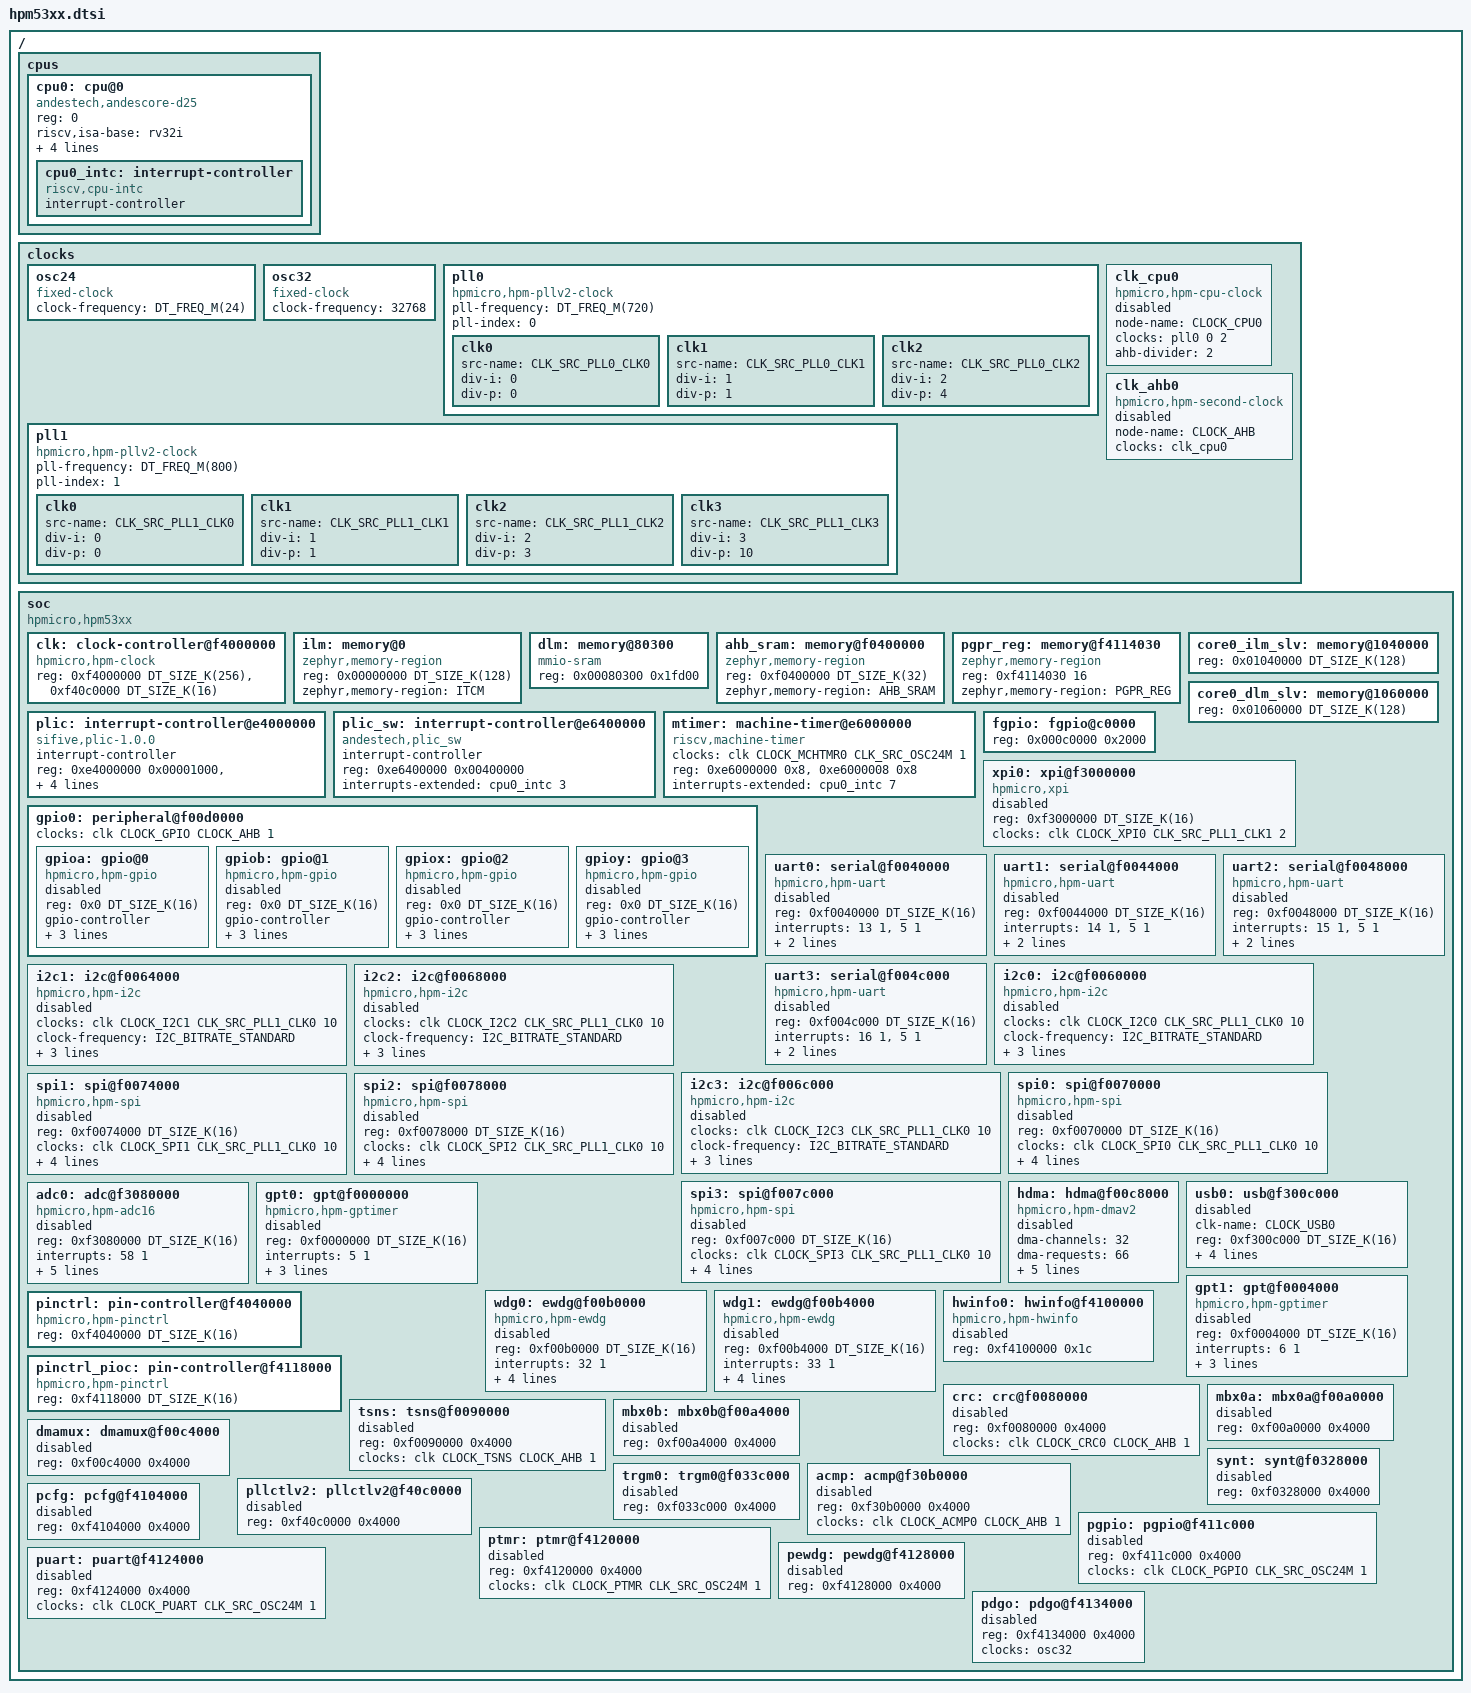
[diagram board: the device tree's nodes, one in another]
/*
* Copyright (c) 2026 HPMicro
* SPDX-License-Identifier: Apache-2.0
*/

/dts-v1/;

#include <zephyr/dt-bindings/gpio/gpio.h>
#include <zephyr/dt-bindings/i2c/i2c.h>
#include <mem.h>
#include <freq.h>

/ {
	#address-cells = <1>;
	#size-cells = <1>;
	cpus {
		#address-cells = <1>;
		#size-cells = <0>;
		cpu0: cpu@0 {
			compatible = "andestech,andescore-d25", "riscv";
			reg = <0>;
			status = "okay";
			riscv,isa-base = "rv32i";
			riscv,isa-extensions = "i", "m", "a", "c", "f", "d", "b", "p", "zicsr", "zifencei",
				"xandes";
			i-cache-line-size = <32>;
			d-cache-line-size = <32>;
			cpu0_intc: interrupt-controller {
				compatible = "riscv,cpu-intc";
				#address-cells = <0>;
				#interrupt-cells = <1>;
				interrupt-controller;
			};
		};
	};

	clocks {
		osc24: osc24 {
			#clock-cells = <0>;
			compatible = "fixed-clock";
			clock-frequency = <DT_FREQ_M(24)>;
		};

		osc32: osc32 {
			#clock-cells = <0>;
			compatible = "fixed-clock";
			clock-frequency = <32768>;
		};

		pll0: pll0 {
			#clock-cells = <2>;
			compatible = "hpmicro,hpm-pllv2-clock";
			pll-frequency = <DT_FREQ_M(720)>;
			pll-index = <0>;
			clk0 {
				src-name = <CLK_SRC_PLL0_CLK0>;
				div-i = <0>;
				div-p = <0>;
			};

			clk1 {
				src-name = <CLK_SRC_PLL0_CLK1>;
				div-i = <1>;
				div-p = <1>;
			};

			clk2 {
				src-name = <CLK_SRC_PLL0_CLK2>;
				div-i = <2>;
				div-p = <4>;
			};
		};

		pll1: pll1 {
			#clock-cells = <2>;
			compatible = "hpmicro,hpm-pllv2-clock";
			pll-frequency = <DT_FREQ_M(800)>;
			pll-index = <1>;
			clk0 {
				src-name = <CLK_SRC_PLL1_CLK0>;
				div-i = <0>;
				div-p = <0>;
			};

			clk1 {
				src-name = <CLK_SRC_PLL1_CLK1>;
				div-i = <1>;
				div-p = <1>;
			};

			clk2 {
				src-name = <CLK_SRC_PLL1_CLK2>;
				div-i = <2>;
				div-p = <3>;
			};

			clk3 {
				src-name = <CLK_SRC_PLL1_CLK3>;
				div-i = <3>;
				div-p = <10>;
			};
		};

		clk_cpu0: clk_cpu0 {
			#clock-cells = <0>;
			compatible = "hpmicro,hpm-cpu-clock";
			node-name = <CLOCK_CPU0>;
			clocks = <&pll0 0 2>;
			ahb-divider = <2>;
			status = "disabled";
		};

		clk_ahb0: clk_ahb0 {
			#clock-cells = <0>;
			compatible = "hpmicro,hpm-second-clock";
			node-name = <CLOCK_AHB>;
			clocks = <&clk_cpu0>;
			status = "disabled";
		};
	};

	soc {
		#address-cells = <1>;
		#size-cells = <1>;
		compatible = "hpmicro,hpm53xx";
		ranges;
		clk: clock-controller@f4000000 {
			compatible = "hpmicro,hpm-clock";
			reg = <0xf4000000 DT_SIZE_K(256)>,
				<0xf40c0000 DT_SIZE_K(16)>;
			reg-names = "sysctl", "pllv2";
			status = "okay";
			#clock-cells = <3>;
		};

		ilm: memory@0 {
			compatible = "zephyr,memory-region";
			reg = <0x00000000 DT_SIZE_K(128)>;
			zephyr,memory-region = "ITCM";
		};

		dlm: memory@80300 {
			compatible = "mmio-sram";
			reg = <0x00080300 0x1fd00>;
		};

		ahb_sram: memory@f0400000 {
			compatible = "zephyr,memory-region";
			reg = <0xf0400000 DT_SIZE_K(32)>;
			zephyr,memory-region = "AHB_SRAM";
		};

		pgpr_reg: memory@f4114030 {
			compatible = "zephyr,memory-region";
			reg = <0xf4114030 16>;
			zephyr,memory-region = "PGPR_REG";
		};

		core0_ilm_slv: memory@1040000 {
			reg = <0x01040000 DT_SIZE_K(128)>;
		};

		core0_dlm_slv: memory@1060000 {
			reg = <0x01060000 DT_SIZE_K(128)>;
		};

		plic: interrupt-controller@e4000000 {
			compatible = "sifive,plic-1.0.0";
			#address-cells = <1>;
			#interrupt-cells = <2>;
			interrupt-controller;
			reg = <0xe4000000 0x00001000>,
				<0xe4002000 0x00000800>,
				<0xe4200000 0x00010000>;
			reg-names = "prio", "irq_en", "reg";
			riscv,max-priority = <31>;
			riscv,ndev = <73>;
			interrupts-extended = <&cpu0_intc 11>;
		};

		plic_sw: interrupt-controller@e6400000 {
			compatible = "andestech,plic_sw";
			#address-cells = <1>;
			#interrupt-cells = <2>;
			interrupt-controller;
			reg = <0xe6400000 0x00400000>;
			interrupts-extended = <&cpu0_intc 3>;
		};

		mtimer: machine-timer@e6000000 {
			compatible = "riscv,machine-timer";
			clocks = <&clk CLOCK_MCHTMR0 CLK_SRC_OSC24M 1>;
			reg = <0xe6000000 0x8>,
				<0xe6000008 0x8>;
			reg-names = "mtime", "mtimecmp";
			interrupts-extended = <&cpu0_intc 7>;
		};

		fgpio: fgpio@c0000 {
			reg = <0x000c0000 0x2000>;
		};

		xpi0: xpi@f3000000 {
			compatible = "hpmicro,xpi";
			reg = <0xf3000000 DT_SIZE_K(16)>;
			clocks = <&clk CLOCK_XPI0 CLK_SRC_PLL1_CLK1 2>;
			#address-cells = <1>;
			#size-cells = <1>;
			status = "disabled";
		};

		gpio0: peripheral@f00d0000 {
			#address-cells = <1>;
			#size-cells = <1>;
			ranges = <0x0 0xf00d0000 DT_SIZE_K(16)>;
			clocks = <&clk CLOCK_GPIO CLOCK_AHB 1>;
		};

		uart0: serial@f0040000 {
			compatible = "hpmicro,hpm-uart";
			reg = <0xf0040000 DT_SIZE_K(16)>;
			interrupts = <13 1>, <5 1>;
			interrupt-names = "uart", "idletimer";
			clocks = <&clk CLOCK_UART0 CLK_SRC_PLL1_CLK0 10>;
			interrupt-parent = <&plic>;
			status = "disabled";
		};

		uart1: serial@f0044000 {
			compatible = "hpmicro,hpm-uart";
			reg = <0xf0044000 DT_SIZE_K(16)>;
			interrupts = <14 1>, <5 1>;
			interrupt-names = "uart", "idletimer";
			clocks = <&clk CLOCK_UART1 CLK_SRC_PLL1_CLK0 10>;
			interrupt-parent = <&plic>;
			status = "disabled";
		};

		uart2: serial@f0048000 {
			compatible = "hpmicro,hpm-uart";
			reg = <0xf0048000 DT_SIZE_K(16)>;
			interrupts = <15 1>, <5 1>;
			interrupt-names = "uart", "idletimer";
			clocks = <&clk CLOCK_UART2 CLK_SRC_PLL1_CLK0 10>;
			interrupt-parent = <&plic>;
			status = "disabled";
		};

		uart3: serial@f004c000 {
			compatible = "hpmicro,hpm-uart";
			reg = <0xf004c000 DT_SIZE_K(16)>;
			interrupts = <16 1>, <5 1>;
			interrupt-names = "uart", "idletimer";
			clocks = <&clk CLOCK_UART3 CLK_SRC_PLL1_CLK0 10>;
			interrupt-parent = <&plic>;
			status = "disabled";
		};

		i2c0: i2c@f0060000 {
			compatible = "hpmicro,hpm-i2c";
			#address-cells = <1>;
			#size-cells = <0>;
			clocks = <&clk CLOCK_I2C0 CLK_SRC_PLL1_CLK0 10>;
			clock-frequency = <I2C_BITRATE_STANDARD>;
			reg = <0xf0060000 DT_SIZE_K(16)>;
			interrupts = <21 1>;
			interrupt-parent = <&plic>;
			status = "disabled";
		};

		i2c1: i2c@f0064000 {
			compatible = "hpmicro,hpm-i2c";
			#address-cells = <1>;
			#size-cells = <0>;
			clocks = <&clk CLOCK_I2C1 CLK_SRC_PLL1_CLK0 10>;
			clock-frequency = <I2C_BITRATE_STANDARD>;
			reg = <0xf0064000 DT_SIZE_K(16)>;
			interrupts = <22 1>;
			interrupt-parent = <&plic>;
			status = "disabled";
		};

		i2c2: i2c@f0068000 {
			compatible = "hpmicro,hpm-i2c";
			#address-cells = <1>;
			#size-cells = <0>;
			clocks = <&clk CLOCK_I2C2 CLK_SRC_PLL1_CLK0 10>;
			clock-frequency = <I2C_BITRATE_STANDARD>;
			reg = <0xf0068000 DT_SIZE_K(16)>;
			interrupts = <23 1>;
			interrupt-parent = <&plic>;
			status = "disabled";
		};

		i2c3: i2c@f006c000 {
			compatible = "hpmicro,hpm-i2c";
			#address-cells = <1>;
			#size-cells = <0>;
			clocks = <&clk CLOCK_I2C3 CLK_SRC_PLL1_CLK0 10>;
			clock-frequency = <I2C_BITRATE_STANDARD>;
			reg = <0xf006c000 DT_SIZE_K(16)>;
			interrupts = <24 1>;
			interrupt-parent = <&plic>;
			status = "disabled";
		};

		spi0: spi@f0070000 {
			compatible = "hpmicro,hpm-spi";
			reg = <0xf0070000 DT_SIZE_K(16)>;
			clocks = <&clk CLOCK_SPI0 CLK_SRC_PLL1_CLK0 10>;
			interrupts = <25 1>;
			interrupt-parent = <&plic>;
			#address-cells = <1>;
			#size-cells = <0>;
			cs-sck-delay = <3>;
			cs-minimum-high-time = <11>;
			status = "disabled";
		};

		spi1: spi@f0074000 {
			compatible = "hpmicro,hpm-spi";
			reg = <0xf0074000 DT_SIZE_K(16)>;
			clocks = <&clk CLOCK_SPI1 CLK_SRC_PLL1_CLK0 10>;
			interrupts = <26 1>;
			interrupt-parent = <&plic>;
			#address-cells = <1>;
			#size-cells = <0>;
			cs-sck-delay = <3>;
			cs-minimum-high-time = <11>;
			status = "disabled";
		};

		spi2: spi@f0078000 {
			compatible = "hpmicro,hpm-spi";
			reg = <0xf0078000 DT_SIZE_K(16)>;
			clocks = <&clk CLOCK_SPI2 CLK_SRC_PLL1_CLK0 10>;
			interrupts = <27 1>;
			interrupt-parent = <&plic>;
			#address-cells = <1>;
			#size-cells = <0>;
			cs-sck-delay = <3>;
			cs-minimum-high-time = <11>;
			status = "disabled";
		};

		spi3: spi@f007c000 {
			compatible = "hpmicro,hpm-spi";
			reg = <0xf007c000 DT_SIZE_K(16)>;
			clocks = <&clk CLOCK_SPI3 CLK_SRC_PLL1_CLK0 10>;
			interrupts = <28 1>;
			interrupt-parent = <&plic>;
			#address-cells = <1>;
			#size-cells = <0>;
			cs-sck-delay = <3>;
			cs-minimum-high-time = <11>;
			status = "disabled";
		};

		hdma: hdma@f00c8000 {
			#dma-cells = <2>;
			compatible = "hpmicro,hpm-dmav2";
			dma-channels = <32>;
			dma-requests = <66>;
			reg = <0xf00c8000 DT_SIZE_K(16)>,
				<0xf00c4000 DT_SIZE_K(16)>;
			interrupts = <34 1>;
			interrupt-parent = <&plic>;
			clocks = <&clk CLOCK_HDMA CLOCK_AHB 1>;
			status = "disabled";
		};

		usb0: usb@f300c000 {
			clk-name = <CLOCK_USB0>;
			reg = <0xf300c000 DT_SIZE_K(16)>;
			interrupts = <51 1>;
			interrupt-parent = <&plic>;
			clocks = <&clk CLOCK_USB0 CLOCK_AHB 1>;
			num-bidir-endpoints = <16>;
			status = "disabled";
		};

		adc0: adc@f3080000 {
			compatible = "hpmicro,hpm-adc16";
			reg = <0xf3080000 DT_SIZE_K(16)>;
			interrupts = <58 1>;
			interrupt-parent = <&plic>;
			clocks = <&clk CLOCK_ADC0 CLK_ADC_SRC_AHB0 1>,
				<&clk CLOCK_AHB CLOCK_CPU0 2>;
			adc-clk-div = <4>;
			sample-time = <20>;
			#io-channel-cells = <1>;
			status = "disabled";
		};

		gpt0: gpt@f0000000 {
			compatible = "hpmicro,hpm-gptimer";
			reg = <0xf0000000 DT_SIZE_K(16)>;
			interrupts = <5 1>;
			interrupt-parent = <&plic>;
			gptfreq = <100000000>;
			clocks = <&clk CLOCK_GPTMR0 CLK_SRC_PLL1_CLK0 8>;
			status = "disabled";
		};

		gpt1: gpt@f0004000 {
			compatible = "hpmicro,hpm-gptimer";
			reg = <0xf0004000 DT_SIZE_K(16)>;
			interrupts = <6 1>;
			interrupt-parent = <&plic>;
			gptfreq = <100000000>;
			clocks = <&clk CLOCK_GPTMR1 CLK_SRC_PLL1_CLK0 8>;
			status = "disabled";
		};

		wdg0: ewdg@f00b0000 {
			compatible = "hpmicro,hpm-ewdg";
			reg = <0xf00b0000 DT_SIZE_K(16)>;
			interrupts = <32 1>;
			interrupt-parent = <&plic>;
			clocks = <&clk CLOCK_WATCHDOG0 CLK_WDG_SRC_OSC32K 1>;
			reset_none_intr;
			status = "disabled";
		};

		wdg1: ewdg@f00b4000 {
			compatible = "hpmicro,hpm-ewdg";
			reg = <0xf00b4000 DT_SIZE_K(16)>;
			interrupts = <33 1>;
			interrupt-parent = <&plic>;
			clocks = <&clk CLOCK_WATCHDOG1 CLK_WDG_SRC_OSC32K 1>;
			reset_none_intr;
			status = "disabled";
		};

		hwinfo0: hwinfo@f4100000 {
			compatible = "hpmicro,hpm-hwinfo";
			reg = <0xf4100000 0x1c>;
			status = "disabled";
		};

		pinctrl: pin-controller@f4040000 {
			compatible = "hpmicro,hpm-pinctrl";
			reg = <0xf4040000 DT_SIZE_K(16)>;
			status = "okay";
		};

		pinctrl_pioc: pin-controller@f4118000 {
			compatible = "hpmicro,hpm-pinctrl";
			reg = <0xf4118000 DT_SIZE_K(16)>;
			status = "okay";
		};

		crc: crc@f0080000 {
			reg = <0xf0080000 0x4000>;
			clocks = <&clk CLOCK_CRC0 CLOCK_AHB 1>;
			status = "disabled";
		};

		tsns: tsns@f0090000 {
			reg = <0xf0090000 0x4000>;
			clocks = <&clk CLOCK_TSNS CLOCK_AHB 1>;
			status = "disabled";
		};

		mbx0a: mbx0a@f00a0000 {
			reg = <0xf00a0000 0x4000>;
			status = "disabled";
		};

		mbx0b: mbx0b@f00a4000 {
			reg = <0xf00a4000 0x4000>;
			status = "disabled";
		};

		dmamux: dmamux@f00c4000 {
			reg = <0xf00c4000 0x4000>;
			status = "disabled";
		};

		synt: synt@f0328000 {
			reg = <0xf0328000 0x4000>;
			status = "disabled";
		};

		trgm0: trgm0@f033c000 {
			reg = <0xf033c000 0x4000>;
			status = "disabled";
		};

		acmp: acmp@f30b0000 {
			reg = <0xf30b0000 0x4000>;
			clocks = <&clk CLOCK_ACMP0 CLOCK_AHB 1>;
			status = "disabled";
		};

		pllctlv2: pllctlv2@f40c0000 {
			reg = <0xf40c0000 0x4000>;
			status = "disabled";
		};

		pcfg: pcfg@f4104000 {
			reg = <0xf4104000 0x4000>;
			status = "disabled";
		};

		pgpio: pgpio@f411c000 {
			reg = <0xf411c000 0x4000>;
			clocks = <&clk CLOCK_PGPIO CLK_SRC_OSC24M 1>;
			status = "disabled";
		};

		ptmr: ptmr@f4120000 {
			reg = <0xf4120000 0x4000>;
			clocks = <&clk CLOCK_PTMR CLK_SRC_OSC24M 1>;
			status = "disabled";
		};

		puart: puart@f4124000 {
			reg = <0xf4124000 0x4000>;
			clocks = <&clk CLOCK_PUART CLK_SRC_OSC24M 1>;
			status = "disabled";
		};

		pewdg: pewdg@f4128000 {
			reg = <0xf4128000 0x4000>;
			status = "disabled";
		};

		pdgo: pdgo@f4134000 {
			reg = <0xf4134000 0x4000>;
			clocks = <&osc32>;
			status = "disabled";
		};
	};
};

&gpio0 {
	gpioa: gpio@0 {
		compatible = "hpmicro,hpm-gpio";
		reg = <0x0 DT_SIZE_K(16)>;
		gpio-controller;
		#gpio-cells = <2>;
		hpmicro-gpio-port = <0>;
		interrupts = <1 1>;
		interrupt-parent = <&plic>;
		status = "disabled";
	};

	gpiob: gpio@1 {
		compatible = "hpmicro,hpm-gpio";
		reg = <0x0 DT_SIZE_K(16)>;
		gpio-controller;
		#gpio-cells = <2>;
		hpmicro-gpio-port = <1>;
		interrupts = <2 1>;
		interrupt-parent = <&plic>;
		status = "disabled";
	};

	gpiox: gpio@2 {
		compatible = "hpmicro,hpm-gpio";
		reg = <0x0 DT_SIZE_K(16)>;
		gpio-controller;
		#gpio-cells = <2>;
		hpmicro-gpio-port = <13>;
		interrupts = <3 1>;
		interrupt-parent = <&plic>;
		status = "disabled";
	};

	gpioy: gpio@3 {
		compatible = "hpmicro,hpm-gpio";
		reg = <0x0 DT_SIZE_K(16)>;
		gpio-controller;
		#gpio-cells = <2>;
		hpmicro-gpio-port = <14>;
		interrupts = <4 1>;
		interrupt-parent = <&plic>;
		status = "disabled";
	};
};
